# TMS320F280049 register map
Vendor: Texas Instruments; Series: C2000 F28004x; File version: 0.2.0-generated
Registers are 16-bit, read-write, reset 0x0 unless marked. A register's access mark holds for its fields unless they carry their own. Offsets are from the block's base; [hi:lo] are bit positions; {n}, {i} and the like mark numbered series.

## DCSMBANK1Z1REGS — DCSM BANK1 Z1 Registers
Base 0x000BE200
0x00 B1_Z1_LINKPOINTER 32-bit — Zone 1 Link Pointer for flash BANK1
  [31:28] LINKPOINTER — Zone1 LINK Pointer in Flash BANK1
0x0C B1_Z1_LINKPOINTERERR 32-bit — Link Pointer Error for flash BANK1
  [31:28] Z1_LINKPOINTERERR — Error to Resolve Z1 Link pointer from OTP loaded values
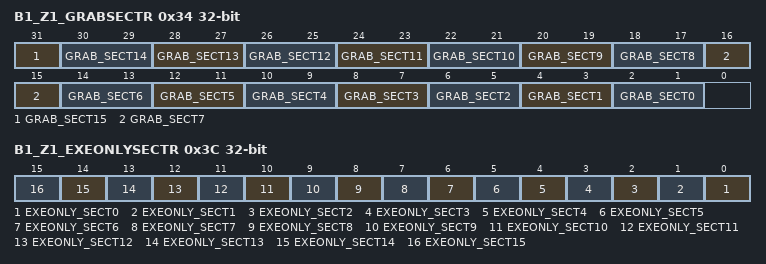
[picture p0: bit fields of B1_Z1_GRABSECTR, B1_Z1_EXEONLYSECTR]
0x34 B1_Z1_GRABSECTR 32-bit — Zone 1 Grab Flash BANK1 Sectors Register
  [31] GRAB_SECT15 — Grab Flash Sector 15 in BANK1
  [2n+2:2n+1] GRAB_SECT{n} (n=0..14) — Grab Flash Sector {n} in BANK1
0x3C B1_Z1_EXEONLYSECTR 32-bit — Zone 1 Flash BANK1 Execute_Only Sector Register
  [n] EXEONLY_SECT{n} (n=0..15) — Execute-Only Flash Sector {n} in Flash BANK1

## DCSMBANK1Z2REGS — DCSM BANK1 Z2 Registers
Base 0x000BE280
0x00 B1_Z2_LINKPOINTER 32-bit — Zone 2 Link Pointer for flash BANK1
  [31:28] LINKPOINTER — Zone2 LINK Pointer in Flash BANK1
0x0C B1_Z2_LINKPOINTERERR 32-bit — Link Pointer Error for flash BANK1
  [31:28] Z2_LINKPOINTERERR — Error to Resolve Z2 Link pointer from OTP loaded values
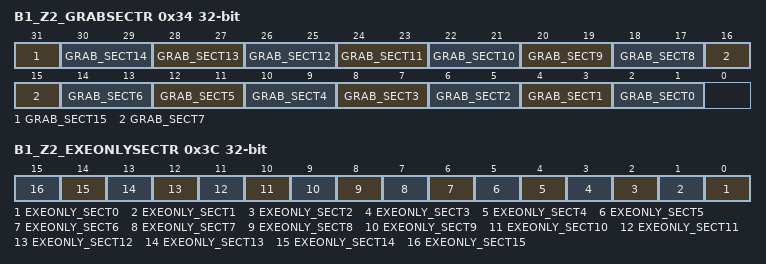
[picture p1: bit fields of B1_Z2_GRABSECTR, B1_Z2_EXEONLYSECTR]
0x34 B1_Z2_GRABSECTR 32-bit — Zone 2 Grab Flash BANK1 Sectors Register
  [31] GRAB_SECT15 — Grab Flash Sector 15 in Flash BANK1
  [2n+2:2n+1] GRAB_SECT{n} (n=0..14) — Grab Flash Sector {n} in Flash BANK1
0x3C B1_Z2_EXEONLYSECTR 32-bit — Zone 2 Flash BANK1 Execute_Only Sector Register
  [n] EXEONLY_SECT{n} (n=0..15) — Execute-Only Flash Sector {n} in Flash BANK1

## MEMORYERRORREGS — MEMORY ERROR Registers
Base 0x000BEA00
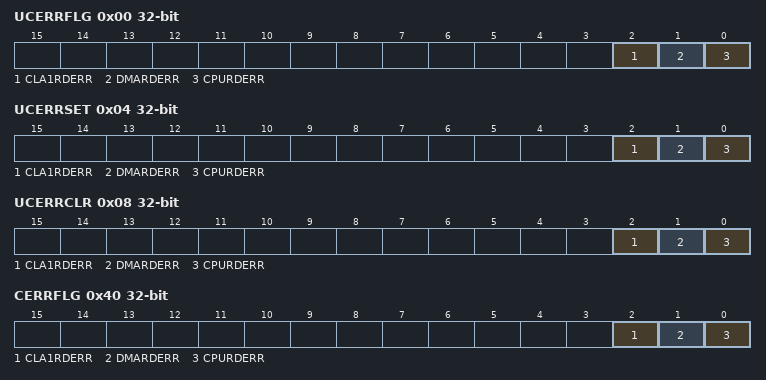
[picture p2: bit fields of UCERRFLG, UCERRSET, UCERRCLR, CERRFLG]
0x00 UCERRFLG 32-bit — Uncorrectable Error Flag Register
  [2] CLA1RDERR — CLA1 Uncorrectable Read Error Flag
  [1] DMARDERR — DMA Uncorrectable Read Error Flag
  [0] CPURDERR — CPU Uncorrectable Read Error Flag
0x04 UCERRSET 32-bit — Uncorrectable Error Flag Set Register
  [2] CLA1RDERR — CLA1 Uncorrectable Read Error Flag Set
  [1] DMARDERR — DMA Uncorrectable Read Error Flag Set
  [0] CPURDERR — CPU Uncorrectable Read Error Flag Set
0x08 UCERRCLR 32-bit — Uncorrectable Error Flag Clear Register
  [2] CLA1RDERR — CLA1 Uncorrectable Read Error Flag Clear
  [1] DMARDERR — DMA Uncorrectable Read Error Flag Clear
  [0] CPURDERR — CPU Uncorrectable Read Error Flag Clear
0x0C UCCPUREADDR 32-bit — Uncorrectable CPU Read Error Address
  [31] UCCPUREADDR — Uncorrectable CPU read/fetch access address register.
0x10 UCDMAREADDR 32-bit — Uncorrectable DMA Read Error Address
  [31] UCDMAREADDR — Uncorrectable DMA read access address register.
0x14 UCCLA1READDR 32-bit — Uncorrectable CLA1 Read Error Address
  [31] UCCLA1READDR — Uncorrectable CLA1 read/fetch access address register.
0x40 CERRFLG 32-bit — Correctable Error Flag Register
  [2] CLA1RDERR — CLA1 Correctable Read Error Flag
  [1] DMARDERR — DMA Correctable Read Error Flag
  [0] CPURDERR — CPU Correctable Read Error Flag
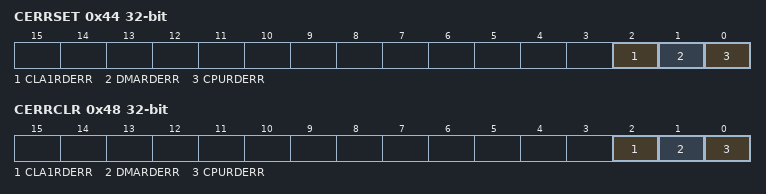
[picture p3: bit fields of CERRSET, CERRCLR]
0x44 CERRSET 32-bit — Correctable Error Flag Set Register
  [2] CLA1RDERR — CLA1 Correctable Read Error Flag Set
  [1] DMARDERR — DMA Correctable Read Error Flag Set
  [0] CPURDERR — CPU Correctable Read Error Flag Set
0x48 CERRCLR 32-bit — Correctable Error Flag Clear Register
  [2] CLA1RDERR — CLA1 Correctable Read Error Flag Clear
  [1] DMARDERR — DMA Correctable Read Error Flag Clear
  [0] CPURDERR — CPU Correctable Read Error Flag Clear
0x4C CCPUREADDR 32-bit — Correctable CPU Read Error Address
  [31] CCPUREADDR — Correctable CPU read/fetch access address register.
0x5C CERRCNT 32-bit — Correctable Error Count Register
  [31] CERRCNT — Correctable error count.
0x60 CERRTHRES 32-bit — Correctable Error Threshold Value Register
  [31] CERRTHRES — Correctable error threshold.
0x64 CEINTFLG 32-bit — Correctable Error Interrupt Flag Status Register
  [0] CEINTFLAG — Total corrected error count exceeded threshold flag.
0x68 CEINTCLR 32-bit — Correctable Error Interrupt Flag Clear Register
  [0] CEINTCLR — CPU Corrected Error Threshold Exceeded Error Clear.
0x6C CEINTSET 32-bit — Correctable Error Interrupt Flag Set Register
  [0] CEINTSET — Total corrected error count exceeded flag set.
0x70 CEINTEN 32-bit — Correctable Error Interrupt Enable Register
  [0] CEINTEN — CPU/DMA Correctable Error Interrupt Enable.
